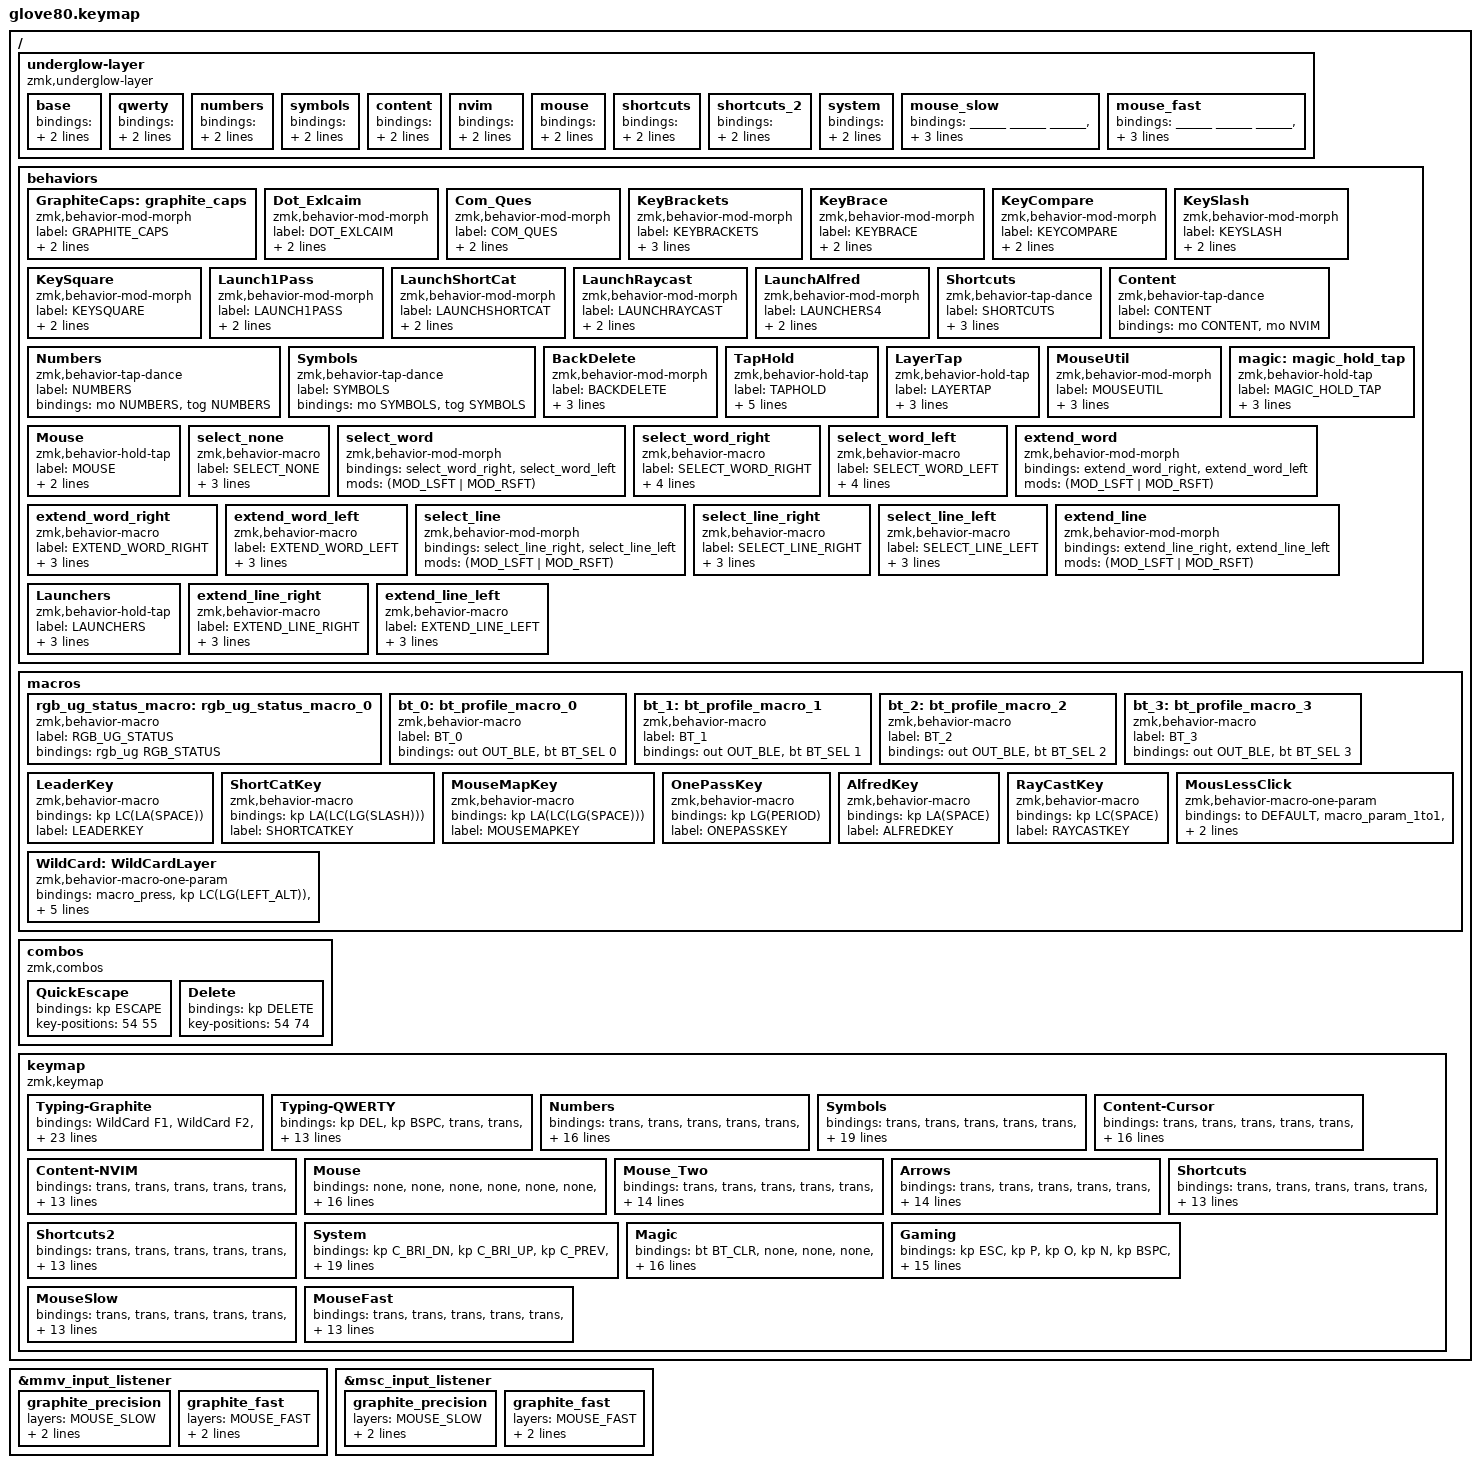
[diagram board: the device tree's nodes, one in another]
/*
 * Graphite update - 2026-10-28
 * Caps Word / Shift+Caps Lock; hold-to-slow/fast mouse; KEYS host shortcut.
 * Graphite letter positions and existing thumb bindings are preserved.
 * Requires the original build's underglow-layer support plus input processors
 * with zip_xy_scaler/zip_scroll_scaler (MoErgo 25.04+ or a compatible fork).
 * See README.md for physical keys, host binding, and validation limitations.
 */
/*
 * Glove 80 Keymap
 *
 * Contents:
 * 1. Includes
 * 2. Layer Defninitons
 * 3. Shortcut Defninitons
 * 4. Color Definitions
 * 5. Layer Colors
 * 6. Color Maps
 * 7. Behaviours
 * 8. macros
 * 9. Combos
 * 10. Keymaps
 *
 */
/************
*  1. Includes
*********************/

#include <behaviors.dtsi>
#include <dt-bindings/zmk/bt.h>
#include <dt-bindings/zmk/keys.h>
#include <dt-bindings/zmk/outputs.h>
#include <dt-bindings/zmk/pointing.h>
#include <input/processors.dtsi>
#include <dt-bindings/zmk/rgb.h>

/************
*  2. Layer Defninitons
*********************/

#define DEFAULT        0
#define QWERTY         1
#define NUMBERS        2
#define SYMBOLS        3
#define CONTENT        4
#define NVIM           5
#define MOUSE          6
#define MOUSE_SCROLL   7
#define ARROWS         8
#define SHORTCUTS      9
#define SHORTCUTS_2    10
#define SYSTEM         11
#define MAGIC          12
#define GAMING         13
#define MOUSE_SLOW     14
#define MOUSE_FAST     15

/* Mouse scaling: multiplier / divisor. Slow wins if both keys are held.
 * Pointer: normal 1x, slow 1/4x, fast 3x.
 * Scroll: normal 1x, slow 1/2x, fast 2x; horizontal scroll is scaled too.
 */
#define POINTER_SLOW_MULT 1
#define POINTER_SLOW_DIV  4
#define POINTER_FAST_MULT 3
#define POINTER_FAST_DIV  1
#define SCROLL_SLOW_MULT  1
#define SCROLL_SLOW_DIV   2
#define SCROLL_FAST_MULT  2
#define SCROLL_FAST_DIV   1

&mmv_input_listener {
    graphite_precision {
        layers = <MOUSE_SLOW>;
        input-processors = <&zip_xy_scaler POINTER_SLOW_MULT POINTER_SLOW_DIV>;
    };
    graphite_fast {
        layers = <MOUSE_FAST>;
        input-processors = <&zip_xy_scaler POINTER_FAST_MULT POINTER_FAST_DIV>;
    };
};

&msc_input_listener {
    graphite_precision {
        layers = <MOUSE_SLOW>;
        input-processors = <&zip_scroll_scaler SCROLL_SLOW_MULT SCROLL_SLOW_DIV>;
    };
    graphite_fast {
        layers = <MOUSE_FAST>;
        input-processors = <&zip_scroll_scaler SCROLL_FAST_MULT SCROLL_FAST_DIV>;
    };
};

/************
* 3. Shortcut Defninitons
*********************/

#define WildModifier  &kp LC(LG(LEFT_ALT))

/***********
* 4. Color Definitions
*********************/

#define COLOR_BLACK        0x000000
#define COLOR_WHITE        0xFFFFFF
#define COLOR_SKY_BLUE     0x66B3FF
#define COLOR_DEEP_BLUE    0x005F99
#define COLOR_LIGHT_BLUE   0x80CFFF
#define COLOR_BRIGHT_GREEN 0x00E673
#define COLOR_ORANGE       0xFF9933
#define COLOR_PURPLE       0x9900FF
#define COLOR_DEEP_PURPLE  0x0900FF
#define COLOR_DARK_RED     0xB30000
#define COLOR_GOLD         0xC49A21
#define COLOR_DEEP_TEAL    0x005F73

/***********
* 5. Layer Colors
*********************/

#define ______  &ug COLOR_BLACK
#define _DFLT_  &ug COLOR_BLACK
#define _QWTY_  &ug COLOR_WHITE
#define _NMBR_  &ug COLOR_SKY_BLUE
#define _SYMB_  &ug COLOR_DEEP_BLUE
#define _CONT_  &ug COLOR_ORANGE
#define _NVIM_  &ug COLOR_PURPLE
#define _MSE__  &ug COLOR_BRIGHT_GREEN
#define _MSEF_  &ug COLOR_BRIGHT_GREEN
#define _MSES_  &ug COLOR_BRIGHT_GREEN
#define _HLP__  &ug COLOR_DEEP_TEAL
#define _HLP2_  &ug COLOR_DEEP_TEAL
#define _SYST_  &ug COLOR_DARK_RED
#define _MAGC_  &ug COLOR_GOLD

/***********
 * 6. Color Maps
*********************/
/* Blank Example:

    mylayer {
        bindings = <
______ ______ ______ ______ ______                                                                    ______ ______ ______ ______ ______
______ ______ ______ ______ ______ ______                                                      ______ ______ ______ ______ ______ ______
______ ______ ______ ______ ______ ______                                                      ______ ______ ______ ______ ______ ______
______ ______ ______ ______ ______ ______                                                      ______ ______ ______ ______ ______ ______
______ ______ ______ ______ ______ ______ ______ ______ ______            ______ ______ ______ ______ ______ ______ ______ ______ ______
______ ______ ______ ______ ______        ______ ______ ______            ______ ______ ______        ______ ______ ______ ______ ______
        >;
        layer-id = <LAYER_Name>;
    };

*/

/ {
    underglow-layer {
        compatible = "zmk,underglow-layer";

        base {
            bindings = <
______ ______ _DFLT_ _DFLT_ _DFLT_                                                                    _DFLT_ _DFLT_ _DFLT_ ______ ______
______ ______ ______ ______ ______ ______                                                      ______ ______ ______ ______ ______ ______
______ ______ ______ ______ ______ ______                                                      ______ ______ ______ ______ ______ ______
______ ______ ______ ______ ______ ______                                                      ______ ______ ______ ______ ______ ______
______ ______ ______ ______ ______ ______ ______ ______ ______            ______ ______ ______ ______ ______ ______ ______ ______ ______
______ ______ ______ ______ ______        ______ ______ ______            ______ ______ ______        ______ ______ ______ ______ ______
            >;

            layer-id = <DEFAULT>;
        };

        qwerty {
            bindings = <
______ ______ _QWTY_ _QWTY_ _QWTY_                                                                    _QWTY_ _QWTY_ _QWTY_ ______ ______
______ ______ ______ ______ ______ ______                                                      ______ ______ ______ ______ ______ ______
______ ______ ______ ______ ______ ______                                                      ______ ______ ______ ______ ______ ______
______ ______ ______ ______ ______ ______                                                      ______ ______ ______ ______ ______ ______
______ ______ ______ ______ ______ ______ ______ ______ ______            ______ ______ ______ ______ ______ ______ ______ ______ ______
______ ______ ______ ______ ______        ______ ______ ______            ______ ______ ______        ______ ______ ______ ______ ______
            >;

            layer-id = <QWERTY>;
        };

        numbers {
            bindings = <
______ ______ _NMBR_ _NMBR_ _NMBR_                                                                    _NMBR_ _NMBR_ _NMBR_ ______ ______
______ ______ ______ ______ ______ ______                                                      ______ ______ ______ ______ ______ ______
______ ______ ______ ______ ______ ______                                                      ______ ______ ______ ______ ______ ______
______ ______ ______ ______ ______ ______                                                      ______ ______ ______ ______ ______ ______
______ ______ ______ ______ ______ ______ ______ ______ ______            ______ ______ ______ ______ ______ ______ ______ ______ ______
______ ______ ______ ______ ______        ______ ______ ______            ______ ______ ______        ______ ______ ______ ______ ______
            >;

            layer-id = <NUMBERS>;
        };

        symbols {
            bindings = <
______ ______ _SYMB_ _SYMB_ _SYMB_                                                                    _SYMB_ _SYMB_ _SYMB_ ______ ______
______ ______ ______ ______ ______ ______                                                      ______ ______ ______ ______ ______ ______
______ ______ ______ ______ ______ ______                                                      ______ ______ ______ ______ ______ ______
______ ______ ______ ______ ______ ______                                                      ______ ______ ______ ______ ______ ______
______ ______ ______ ______ ______ ______ ______ ______ ______            ______ ______ ______ ______ ______ ______ ______ ______ ______
______ ______ ______ ______ ______        ______ ______ ______            ______ ______ ______        ______ ______ ______ ______ ______
            >;

            layer-id = <SYMBOLS>;
        };

        content {
            bindings = <
______ ______ _CONT_ _CONT_ _CONT_                                                                    _CONT_ _CONT_ _CONT_ ______ ______
______ ______ ______ ______ ______ ______                                                      ______ ______ ______ ______ ______ ______
______ ______ ______ ______ ______ ______                                                      ______ ______ ______ ______ ______ ______
______ ______ ______ ______ ______ ______                                                      ______ ______ ______ ______ ______ ______
______ ______ ______ ______ ______ ______ ______ ______ ______            ______ ______ ______ ______ ______ ______ ______ ______ ______
______ ______ ______ ______ ______        ______ ______ ______            ______ ______ ______        ______ ______ ______ ______ ______
            >;

            layer-id = <CONTENT>;
        };

        nvim {
            bindings = <
______ ______ _NVIM_ _NVIM_ _NVIM_                                                                    _NVIM_ _NVIM_ _NVIM_ ______ ______
______ ______ ______ ______ ______ ______                                                      ______ ______ ______ ______ ______ ______
______ ______ ______ ______ ______ ______                                                      ______ ______ ______ ______ ______ ______
______ ______ ______ ______ ______ ______                                                      ______ ______ ______ ______ ______ ______
______ ______ ______ ______ ______ ______ ______ ______ ______            ______ ______ ______ ______ ______ ______ ______ ______ ______
______ ______ ______ ______ ______        ______ ______ ______            ______ ______ ______        ______ ______ ______ ______ ______
            >;

            layer-id = <NVIM>;
        };

        mouse {
            bindings = <
______ ______ ______ _MSE__ ______                                                                    ______ _MSE__ ______ ______ ______
______ ______ ______ ______ ______ ______                                                      ______ ______ ______ ______ ______ ______
______ ______ ______ ______ ______ ______                                                      ______ ______ ______ ______ ______ ______
______ ______ ______ ______ ______ ______                                                      ______ ______ ______ ______ ______ ______
______ ______ ______ ______ ______ ______ ______ ______ ______            ______ ______ ______ ______ ______ ______ ______ ______ ______
______ ______ ______ ______ ______        ______ ______ ______            ______ ______ ______        ______ ______ ______ ______ ______
            >;

            layer-id = <MOUSE>;
        };

        shortcuts {
            bindings = <
______ ______ ______ ______ _HLP__                                                                    _HLP__ ______ ______ ______ ______
______ ______ ______ ______ ______ ______                                                      ______ ______ ______ ______ ______ ______
______ ______ ______ ______ ______ ______                                                      ______ ______ ______ ______ ______ ______
______ ______ ______ ______ ______ ______                                                      ______ ______ ______ ______ ______ ______
______ ______ ______ ______ ______ ______ ______ ______ ______            ______ ______ ______ ______ ______ ______ ______ ______ ______
______ ______ ______ ______ ______        ______ ______ ______            ______ ______ ______        ______ ______ ______ ______ ______
            >;

            layer-id = <SHORTCUTS>;
        };

        shortcuts_2 {
            bindings = <
______ ______ ______ _HLP2_ _HLP2_                                                                    _HLP2_ _HLP2_ ______ ______ ______
______ ______ ______ ______ ______ ______                                                      ______ ______ ______ ______ ______ ______
______ ______ ______ ______ ______ ______                                                      ______ ______ ______ ______ ______ ______
______ ______ ______ ______ ______ ______                                                      ______ ______ ______ ______ ______ ______
______ ______ ______ ______ ______ ______ ______ ______ ______            ______ ______ ______ ______ ______ ______ ______ ______ ______
______ ______ ______ ______ ______        ______ ______ ______            ______ ______ ______        ______ ______ ______ ______ ______
            >;

            layer-id = <SHORTCUTS_2>;
        };

        system {
            bindings = <
______ ______ _SYST_ _SYST_ _SYST_                                                                    _SYST_ _SYST_ _SYST_ ______ ______
______ ______ ______ ______ ______ ______                                                      ______ ______ ______ ______ ______ ______
______ ______ ______ ______ ______ ______                                                      ______ ______ ______ ______ ______ ______
______ ______ ______ ______ ______ ______                                                      ______ ______ ______ ______ ______ ______
______ ______ ______ ______ ______ ______ ______ ______ ______            ______ ______ ______ ______ ______ ______ ______ ______ ______
______ ______ ______ ______ ______        ______ ______ ______            ______ ______ ______        ______ ______ ______ ______ ______
            >;

            layer-id = <SYSTEM>;
        };

        mouse_slow {
            bindings = <
                ______  ______  ______  &ug COLOR_LIGHT_BLUE  ______  ______  &ug COLOR_LIGHT_BLUE  ______  ______  ______
                ______  ______  ______  ______  ______  ______  ______  ______  ______  ______  ______  ______
                ______  ______  ______  ______  ______  ______  ______  ______  ______  ______  ______  ______
                ______  ______  ______  ______  ______  ______  ______  ______  ______  ______  ______  ______
                ______  ______  ______  ______  ______  ______  ______  ______  ______  ______  ______  ______  ______  ______  ______  ______  ______  ______
                ______  ______  ______  ______  ______  ______  ______  ______  ______  ______  ______  ______  ______  ______  ______  ______
            >;
            layer-id = <MOUSE_SLOW>;
        };

        mouse_fast {
            bindings = <
                ______  ______  ______  &ug COLOR_ORANGE  ______  ______  &ug COLOR_ORANGE  ______  ______  ______
                ______  ______  ______  ______  ______  ______  ______  ______  ______  ______  ______  ______
                ______  ______  ______  ______  ______  ______  ______  ______  ______  ______  ______  ______
                ______  ______  ______  ______  ______  ______  ______  ______  ______  ______  ______  ______
                ______  ______  ______  ______  ______  ______  ______  ______  ______  ______  ______  ______  ______  ______  ______  ______  ______  ______
                ______  ______  ______  ______  ______  ______  ______  ______  ______  ______  ______  ______  ______  ______  ______  ______
            >;
            layer-id = <MOUSE_FAST>;
        };
    };
};

/***********
 * 7. Behaviours
*********************/

/ {
    behaviors {

        // Tap: Caps Word. Hold either Shift and tap: ordinary Caps Lock.
        GraphiteCaps: graphite_caps {
            compatible = "zmk,behavior-mod-morph";
            label = "GRAPHITE_CAPS";
            #binding-cells = <0>;
            bindings = <&caps_word>, <&kp CAPSLOCK>;
            mods = <(MOD_LSFT | MOD_RSFT)>;
        };

        /*****
    /* 7a. Keypairs
    /**********/

        Dot_Exlcaim: Dot_Exlcaim {
            compatible = "zmk,behavior-mod-morph";
            label = "DOT_EXLCAIM";
            bindings = <&kp PERIOD>, <&kp EXCLAMATION>;

            #binding-cells = <0>;
            mods = <(MOD_RSFT|MOD_LSFT)>;
        };

        Com_Ques: Com_Ques {
            compatible = "zmk,behavior-mod-morph";
            label = "COM_QUES";
            bindings = <&kp COMMA>, <&kp QUESTION>;

            #binding-cells = <0>;
            mods = <(MOD_RSFT|MOD_LSFT)>;
        };

        KeyBrackets: KeyBrackets {
            compatible = "zmk,behavior-mod-morph";
            label = "KEYBRACKETS";
            bindings = <&kp LEFT_PARENTHESIS>, <&kp RIGHT_PARENTHESIS>;

            #binding-cells = <0>;
            mods = <(MOD_RSFT|MOD_LSFT)>;
        };

        KeyBrace: KeyBrace {
            compatible = "zmk,behavior-mod-morph";
            label = "KEYBRACE";
            bindings = <&kp LEFT_BRACE>, <&kp RIGHT_BRACE>;

            #binding-cells = <0>;
            mods = <(MOD_RSFT|MOD_LSFT)>;
        };

        KeyCompare: KeyCompare {
            compatible = "zmk,behavior-mod-morph";
            label = "KEYCOMPARE";
            bindings = <&kp LESS_THAN>, <&kp GREATER_THAN>;

            #binding-cells = <0>;
            mods = <(MOD_RSFT|MOD_LSFT)>;
        };

        KeySlash: KeySlash {
            compatible = "zmk,behavior-mod-morph";
            label = "KEYSLASH";
            bindings = <&kp SLASH>, <&kp BACKSLASH>;

            #binding-cells = <0>;
            mods = <(MOD_RSFT|MOD_LSFT)>;
        };

        KeySquare: KeySquare {
            compatible = "zmk,behavior-mod-morph";
            label = "KEYSQUARE";
            bindings = <&kp LEFT_BRACKET>, <&kp RIGHT_BRACKET>;

            #binding-cells = <0>;
            mods = <(MOD_RSFT|MOD_LSFT)>;
        };

        /*****
    /* 7b. Quick Launchers
    /*************/

        Launch1Pass: Launch1Pass {
            compatible = "zmk,behavior-mod-morph";
            label = "LAUNCH1PASS";
            bindings = <&LaunchRaycast>, <&OnePassKey>;

            #binding-cells = <0>;
            mods = <(MOD_LCTL|MOD_RCTL)>;
        };

        LaunchShortCat: LaunchShortCat {
            compatible = "zmk,behavior-mod-morph";
            label = "LAUNCHSHORTCAT";
            bindings = <&LaunchRaycast>, <&ShortCatKey>;

            #binding-cells = <0>;
            mods = <(MOD_RALT|MOD_LALT)>;
        };

        LaunchRaycast: LaunchRaycast {
            compatible = "zmk,behavior-mod-morph";
            label = "LAUNCHRAYCAST";
            bindings = <&LaunchAlfred>, <&RayCastKey>;

            #binding-cells = <0>;
            mods = <(MOD_LALT|MOD_RALT)>;
        };

        LaunchAlfred: LaunchAlfred {
            compatible = "zmk,behavior-mod-morph";
            label = "LAUNCHERS4";
            bindings = <&AlfredKey>, <&LeaderKey>;

            #binding-cells = <0>;
            mods = <(MOD_RGUI|MOD_LGUI)>;
        };

        /*****
    /* 7c. Layer Toggle Keys
    /*************/

        Shortcuts: Shortcuts {
            compatible = "zmk,behavior-tap-dance";
            label = "SHORTCUTS";
            #binding-cells = <0>;
            bindings = <&kp LC(LG(LEFT_ALT))>, <&mo SHORTCUTS_2>, <&mo SYSTEM>;

            tapping-term-ms = <400>;
        };

        Content: Content {
            compatible = "zmk,behavior-tap-dance";
            label = "CONTENT";
            #binding-cells = <0>;
            bindings = <&mo CONTENT>, <&mo NVIM>;
        };

        Numbers: Numbers {
            compatible = "zmk,behavior-tap-dance";
            label = "NUMBERS";
            #binding-cells = <0>;
            bindings = <&mo NUMBERS>, <&tog NUMBERS>;
        };

        Symbols: Symbols {
            compatible = "zmk,behavior-tap-dance";
            label = "SYMBOLS";
            #binding-cells = <0>;
            bindings = <&mo SYMBOLS>, <&tog SYMBOLS>;
        };

        /******
    /* 7d. Delete Backspace Functionality 
    /*************/

        BackDelete: BackDelete {
            compatible = "zmk,behavior-mod-morph";
            label = "BACKDELETE";
            bindings = <&kp BACKSPACE>, <&kp DELETE>;

            #binding-cells = <0>;
            mods = <(MOD_RSFT)>;
            keep-mods = <(MOD_RSFT)>;
        };

        /******
    /* 7e. Internal Helpers
    /*************/

        TapHold: TapHold {
            compatible = "zmk,behavior-hold-tap";
            label = "TAPHOLD";
            bindings = <&kp>, <&kp>;

            #binding-cells = <2>;
            tapping-term-ms = <200>;
            flavor = "hold-preferred";
            hold-while-undecided;
            hold-while-undecided-linger;
        };

        LayerTap: LayerTap {
            compatible = "zmk,behavior-hold-tap";
            label = "LAYERTAP";
            bindings = <&mo>, <&tog>;

            #binding-cells = <2>;
            tapping-term-ms = <150>;
            hold-while-undecided;
        };

        MouseUtil: MouseUtil {
            compatible = "zmk,behavior-mod-morph";
            label = "MOUSEUTIL";
            bindings = <&MouseMapKey>, <&ShortCatKey>;

            #binding-cells = <0>;
            mods = <(MOD_LCTL|MOD_LSFT|MOD_LALT|MOD_LGUI|MOD_RCTL|MOD_RALT|MOD_RSFT|MOD_RGUI)>;
        };

        /******
    /* 7f. Magic Layer/Core
    /*************/

        magic: magic_hold_tap {
            compatible = "zmk,behavior-hold-tap";
            label = "MAGIC_HOLD_TAP";
            #binding-cells = <2>;
            flavor = "tap-preferred";
            tapping-term-ms = <200>;
            bindings = <&mo>, <&rgb_ug_status_macro>;
        };

        Mouse: Mouse {
            compatible = "zmk,behavior-hold-tap";
            label = "MOUSE";
            bindings = <&mo>, <&MouseUtil>;

            #binding-cells = <2>;
            tapping-term-ms = <400>;
        };

        /******
    * 7g. Content Control
    *************/
        // SELECT_WORD_DELAY defines how long the macro waits (milliseconds)
        // after moving the cursor before it selects a word. A larger delay
        // may allow the macro to move to the next word upon each invocation.
        //

        #ifndef SELECT_WORD_DELAY
        #define SELECT_WORD_DELAY 1
        #endif

        #define select_all &kp LC(A)

        // Select None Macro

        select_none: select_none {
            compatible = "zmk,behavior-macro";
            #binding-cells = <0>;
            label = "SELECT_NONE";
            bindings = <&kp DOWN &kp UP &kp RIGHT &kp LEFT>;
            wait-ms = <SELECT_WORD_DELAY>;
            tap-ms = <SELECT_WORD_DELAY>;
        };

        // Select a word (jumps to the next word upon each successive invocation)

        select_word: select_word {
            compatible = "zmk,behavior-mod-morph";
            #binding-cells = <0>;
            bindings = <&select_word_right>, <&select_word_left>;

            mods = <(MOD_LSFT | MOD_RSFT)>;
        };

        // Move Right and Select a Word

        select_word_right: select_word_right {
            compatible = "zmk,behavior-macro";
            #binding-cells = <0>;
            label = "SELECT_WORD_RIGHT";
            bindings = <&kp LA(RIGHT) &kp LA(LEFT) &kp LS(LA(RIGHT))>;
            wait-ms = <SELECT_WORD_DELAY>;
            tap-ms = <SELECT_WORD_DELAY>;
        };

        // Move Left and Select a Word

        select_word_left: select_word_left {
            compatible = "zmk,behavior-macro";
            #binding-cells = <0>;
            label = "SELECT_WORD_LEFT";
            bindings = <&kp LA(LEFT) &kp LA(RIGHT) &kp LS(LA(LEFT))>;
            wait-ms = <SELECT_WORD_DELAY>;
            tap-ms = <SELECT_WORD_DELAY>;
        };

        // Extend current selection by one word

        extend_word: extend_word {
            compatible = "zmk,behavior-mod-morph";
            #binding-cells = <0>;
            bindings = <&extend_word_right>, <&extend_word_left>;

            mods = <(MOD_LSFT | MOD_RSFT)>;
        };

        // Extend selection to the right by one word

        extend_word_right: extend_word_right {
            compatible = "zmk,behavior-macro";
            #binding-cells = <0>;
            label = "EXTEND_WORD_RIGHT";
            bindings = <&kp LS(LA(RIGHT))>;
            wait-ms = <SELECT_WORD_DELAY>;
            tap-ms = <SELECT_WORD_DELAY>;
        };

        // Extend selection to the left by one word

        extend_word_left: extend_word_left {
            compatible = "zmk,behavior-macro";
            #binding-cells = <0>;
            label = "EXTEND_WORD_LEFT";
            bindings = <&kp LS(LA(LEFT))>;
            wait-ms = <SELECT_WORD_DELAY>;
            tap-ms = <SELECT_WORD_DELAY>;
        };

        // Select the entire line

        select_line: select_line {
            compatible = "zmk,behavior-mod-morph";
            #binding-cells = <0>;
            bindings = <&select_line_right>, <&select_line_left>;

            mods = <(MOD_LSFT | MOD_RSFT)>;
        };

        // Select the current line (move cursor to start and then select)

        select_line_right: select_line_right {
            compatible = "zmk,behavior-macro";
            #binding-cells = <0>;
            label = "SELECT_LINE_RIGHT";
            bindings = <&kp LG(LEFT) &kp LS(LG(RIGHT))>;
            wait-ms = <SELECT_WORD_DELAY>;
            tap-ms = <SELECT_WORD_DELAY>;
        };

        // Select the current line (move cursor to end and then select backward)

        select_line_left: select_line_left {
            compatible = "zmk,behavior-macro";
            #binding-cells = <0>;
            label = "SELECT_LINE_LEFT";
            bindings = <&kp LG(RIGHT) &kp LS(LG(LEFT))>;
            wait-ms = <SELECT_WORD_DELAY>;
            tap-ms = <SELECT_WORD_DELAY>;
        };

        // Extend selection to the next line

        extend_line: extend_line {
            compatible = "zmk,behavior-mod-morph";
            #binding-cells = <0>;
            bindings = <&extend_line_right>, <&extend_line_left>;

            mods = <(MOD_LSFT | MOD_RSFT)>;
        };

        Launchers: Launchers {
            compatible = "zmk,behavior-hold-tap";
            label = "LAUNCHERS";
            bindings = <&Shortcuts>, <&Launch1Pass>;

            #binding-cells = <2>;
            tapping-term-ms = <300>;
            hold-while-undecided;
        };

        // Extend selection to the next line downward

        extend_line_right: extend_line_right {
            compatible = "zmk,behavior-macro";
            #binding-cells = <0>;
            label = "EXTEND_LINE_RIGHT";
            bindings = <&kp LS(DOWN) &kp LS(LG(RIGHT))>;
            wait-ms = <SELECT_WORD_DELAY>;
            tap-ms = <SELECT_WORD_DELAY>;
        };

        // Extend selection to the previous line upward

        extend_line_left: extend_line_left {
            compatible = "zmk,behavior-macro";
            #binding-cells = <0>;
            label = "EXTEND_LINE_LEFT";
            bindings = <&kp LS(UP) &kp LS(LG(LEFT))>;
            wait-ms = <SELECT_WORD_DELAY>;
            tap-ms = <SELECT_WORD_DELAY>;
        };
    };
};

/***********
* 8. macros
*********************/

/ {
    macros {
        /******
    /* 8a. Glove80 Core
    /*************/

        rgb_ug_status_macro: rgb_ug_status_macro_0 {
            label = "RGB_UG_STATUS";
            compatible = "zmk,behavior-macro";
            #binding-cells = <0>;
            bindings = <&rgb_ug RGB_STATUS>;
        };

        bt_0: bt_profile_macro_0 {
            label = "BT_0";
            compatible = "zmk,behavior-macro";
            #binding-cells = <0>;
            bindings = <&out OUT_BLE &bt BT_SEL 0>;
        };

        bt_1: bt_profile_macro_1 {
            label = "BT_1";
            compatible = "zmk,behavior-macro";
            #binding-cells = <0>;
            bindings = <&out OUT_BLE &bt BT_SEL 1>;
        };

        bt_2: bt_profile_macro_2 {
            label = "BT_2";
            compatible = "zmk,behavior-macro";
            #binding-cells = <0>;
            bindings = <&out OUT_BLE &bt BT_SEL 2>;
        };

        bt_3: bt_profile_macro_3 {
            label = "BT_3";
            compatible = "zmk,behavior-macro";
            #binding-cells = <0>;
            bindings = <&out OUT_BLE &bt BT_SEL 3>;
        };

        /******
    /* 8b. Shortcut Keys
    /*************/

        LeaderKey: LeaderKey {
            compatible = "zmk,behavior-macro";
            #binding-cells = <0>;
            bindings = <&kp LC(LA(SPACE))>;
            label = "LEADERKEY";
        };

        ShortCatKey: ShortCatKey {
            compatible = "zmk,behavior-macro";
            #binding-cells = <0>;
            bindings = <&kp LA(LC(LG(SLASH)))>;
            label = "SHORTCATKEY";
        };

        MouseMapKey: MouseMapKey {
            compatible = "zmk,behavior-macro";
            #binding-cells = <0>;
            bindings = <&kp LA(LC(LG(SPACE)))>;
            label = "MOUSEMAPKEY";
        };

        OnePassKey: OnePassKey {
            compatible = "zmk,behavior-macro";
            #binding-cells = <0>;
            bindings = <&kp LG(PERIOD)>;
            label = "ONEPASSKEY";
        };

        AlfredKey: AlfredKey {
            compatible = "zmk,behavior-macro";
            #binding-cells = <0>;
            bindings = <&kp LA(SPACE)>;
            label = "ALFREDKEY";
        };

        RayCastKey: RayCastKey {
            compatible = "zmk,behavior-macro";
            #binding-cells = <0>;
            bindings = <&kp LC(SPACE)>;
            label = "RAYCASTKEY";
        };

        MousLessClick: MousLessClick {
            compatible = "zmk,behavior-macro-one-param";
            #binding-cells = <1>;
            bindings = <&to DEFAULT &macro_param_1to1 &kp MACRO_PLACEHOLDER>;
            label = "MOUSLESSCLICK";
        };

        /*********
    /* 8c. Wilds
    /*************/

        WildCard: WildCardLayer {
            compatible = "zmk,behavior-macro-one-param";
            #binding-cells = <1>;
            bindings =
                <&macro_press>,
                <&kp LC(LG(LEFT_ALT))>,
                <&macro_tap>,
                <&macro_param_1to1 &kp MACRO_PLACEHOLDER>,
                <&macro_release>,
                <&kp LC(LG(LEFT_ALT))>;

            tap-ms = <300>;
            label = "WILDCARDLAYER";
        };
    };
};

/***********
* 9. Combos
*********************/

/ {
    combos {
        compatible = "zmk,combos";

        QuickEscape {
            bindings = <&kp ESCAPE>;
            key-positions = <54 55>;
        };

        Delete {
            bindings = <&kp DELETE>;
            key-positions = <54 74>;
        };
    };
};

/***********
* 10. Keymaps
*********************/

/ {
    keymap {
        compatible = "zmk,keymap";

        Typing-Graphite {
            bindings = <
&WildCard F1    &WildCard F2  &WildCard F14     &WildCard F15  &WildCard F16                                                                                                                                                    &WildCard F17      &WildCard F18  &WildCard F19      &WildCard F9                               &WildCard F10
&kp GRAVE       &KeySlash     &KeySquare        &KeyBrace      &KeyBrackets      &KeyCompare                                                                                                                     &kp GRAVE      &kp MINUS          &kp EQUAL      &KeySlash          &kp PIPE                                   &kp LC(LA(LG(LS(F13))))
&GraphiteCaps    &kp B         &kp L             &kp D          &kp W             &kp Z                                                                                                                           &kp K          &kp F              &kp O          &kp U              &kp J                                      &kp ESCAPE
&Mouse MOUSE 0      &kp N         &kp R             &kp T          &kp S             &kp G                                                                                                                           &kp Y          &kp H              &kp A          &kp E              &kp I                                      &kp TAB
&kp LEFT_SHIFT  &kp Q         &kp X             &kp M          &kp C             &kp V        &kp SPACE  &Numbers          &TapHold LC(LG(LEFT_ALT)) LA(LC(LG(F20)))  &Content        &Symbols   &kp LEFT_SHIFT  &kp SEMICOLON  &kp P              &Com_Ques      &Dot_Exlcaim       &kp SQT                                    &kp DEL
&magic MAGIC 0     &Mouse MOUSE 0    &kp LEFT_CONTROL  &kp LEFT_ALT   &kp LEFT_COMMAND               &mo ARROWS      &kp LEFT_COMMAND  &kp LC(LEFT_ALT)                           &Launchers 0 0  &kp ENTER  &kp BACKSPACE                  &kp RIGHT_COMMAND  &kp RIGHT_ALT  &kp RIGHT_CONTROL  &TapHold LC(LG(LEFT_ALT)) LA(LC(LG(F24)))  &kp ESCAPE
            >;
        };

        Typing-QWERTY {
            bindings = <
&kp DEL  &kp BSPC  &trans  &trans  &trans                                                                  &trans  &trans     &trans   &trans    &trans
&trans   &kp N1    &kp N2  &kp N3  &kp N4  &kp N5                                                  &kp N6  &kp N7  &kp N8     &kp N9   &kp N0    &kp MINUS
&kp TAB  &kp Q     &kp W   &kp E   &kp R   &kp T                                                   &kp Y   &kp U   &kp I      &kp O    &kp P     &kp LBKT
&trans   &kp A     &kp S   &kp D   &kp F   &kp G                                                   &kp H   &kp J   &kp K      &kp L    &kp SEMI  &trans
&trans   &kp Z     &kp X   &kp C   &kp V   &kp B   &trans  &trans  &trans  &trans  &trans  &trans  &kp N   &kp M   &kp COMMA  &kp DOT  &kp FSLH  &trans
&trans   &trans    &trans  &trans  &trans          &trans  &trans  &trans  &trans  &trans  &trans          &trans  &trans     &trans   &trans    &trans
            >;
        };

        Numbers {
            bindings = <
&trans  &trans                &trans                 &trans       &trans                                                                               &trans    &trans    &trans     &trans     &trans
&trans  &trans                &trans                 &trans       &trans     &trans                                                       &kp PERCENT  &kp FSLH  &kp STAR  &trans     &trans     &trans
&trans  &kp LEFT_PARENTHESIS  &kp RIGHT_PARENTHESIS  &kp PERIOD   &kp EQUAL  &kp COMMA                                                    &kp DOLLAR   &kp N7    &kp N8    &kp N9     &kp MINUS  &trans
&trans  &kp SLASH             &kp ASTERISK           &kp MINUS    &kp PLUS   &kp COLON                                                    &kp HASH     &kp N4    &kp N5    &kp N6     &kp PLUS   &trans
&trans  &trans                &kp DOLLAR             &kp PERCENT  &kp HASH   &trans     &trans  &trans  &trans  &trans  &trans  &Symbols  &kp COMMA    &kp N1    &kp N2    &kp N3     &kp EQUAL  &trans
&trans  &trans                &trans                 &trans       &trans                &trans  &trans  &trans  &trans  &trans  &trans                 &kp N0    &kp DOT   &kp EQUAL  &trans     &trans
            >;
        };

        Symbols {
            bindings = <
&trans           &trans         &trans                &trans                 &trans                                                                                                &trans           &trans        &trans                &trans  &trans
&kp GRAVE        &kp LBKT       &kp EQUAL             &kp UNDERSCORE         &kp RBKT          &kp DOT                                                                     &trans  &trans           &trans        &trans                &trans  &trans
&kp EXCLAMATION  &kp COMMA      &kp LEFT_BRACE        &kp RIGHT_BRACE        &kp SEMI          &kp QUESTION                                                                &trans  &kp AMPS         &kp ASTERISK  &kp LEFT_PARENTHESIS  &trans  &trans
&kp POUND        &kp CARET      &kp LEFT_PARENTHESIS  &kp RIGHT_PARENTHESIS  &kp DOLLAR        &kp ASTERISK                                                                &trans  &kp DLLR         &kp PRCNT     &kp CARET             &trans  &trans
&kp TILDE        &kp PIPE       &kp LESS_THAN         &kp GREATER_THAN       &kp GREATER_THAN  &kp FSLH      &kp BSLH     &kp DOT    &kp ASTERISK  &trans  &trans  &trans  &trans  &kp EXCLAMATION  &kp AT        &kp HASH              &trans  &trans
&trans           &kp AMPERSAND  &kp SQT               &kp DOUBLE_QUOTES      &kp PLUS                        &kp PERCENT  &kp COLON  &kp AT_SIGN   &trans  &trans  &trans          &trans           &trans        &trans                &trans  &trans
            >;
        };

        Content-Cursor {
            bindings = <
&trans  &trans        &trans     &trans        &trans                                                                                  &trans         &trans         &trans         &trans  &trans
&trans  &trans        &trans     &trans        &trans        &trans                                                         &trans     &kp LG(N0)     &kp LG(MINUS)  &kp LG(EQUAL)  &trans  &trans
&trans  &trans        &trans     &extend_line  &extend_word  &trans                                                         &kp LG(Z)  &kp PAGE_UP    &kp LG(EQUAL)  &kp HOME       &trans  &trans
&trans  &select_none  &kp LG(A)  &select_line  &select_word  &trans                                                         &kp LG(Y)  &kp PAGE_DOWN  &kp LG(N0)     &kp END        &trans  &trans
&trans  &trans        &kp LG(X)  &kp LG(C)     &kp LG(V)     &kp LG(LS(V))  &trans  &trans  &trans  &trans  &trans  &trans  &trans     &trans         &kp LG(MINUS)  &trans         &trans  &trans
&trans  &trans        &trans     &trans        &trans                       &trans  &mo NVIM   &trans  &trans  &trans  &trans             &trans         &trans         &trans         &trans  &trans
            >;
        };

        Content-NVIM {
            bindings = <
&trans  &trans  &trans  &trans  &trans                                                                  &trans  &trans  &trans  &trans  &trans
&trans  &trans  &trans  &trans  &trans  &trans                                                  &trans  &trans  &trans  &trans  &trans  &trans
&trans  &trans  &trans  &trans  &trans  &trans                                                  &trans  &trans  &trans  &trans  &trans  &trans
&trans  &trans  &trans  &trans  &trans  &trans                                                  &trans  &trans  &trans  &trans  &trans  &trans
&trans  &trans  &kp X   &kp Y   &kp P   &trans  &trans  &trans  &trans  &trans  &trans  &trans  &trans  &trans  &trans  &trans  &trans  &trans
&trans  &trans  &trans  &trans  &trans          &trans  &trans  &trans  &trans  &trans  &trans          &trans  &trans  &trans  &trans  &trans
            >;
        };

        Mouse {
            bindings = <
&none  &none      &none         &none         &none                                                                                                     &none              &none              &none             &none  &none
&none  &none      &none         &none         &none         &none                                                                       &none           &none              &none              &none             &none  &none
&none  &mo MOUSE_SLOW      &mo MOUSE_FAST         &kp UP        &none         &kp PAGE_UP                                                                 &msc SCRL_UP    &mkp LCLK          &mmv MOVE_Y(-600)  &mkp RCLK         &none  &none
&none  &kp EQUAL  &kp LEFT      &kp DOWN      &kp RIGHT     &kp PAGE_DOWN                                                               &msc SCRL_DOWN  &mmv MOVE_X(-600)  &mmv MOVE_Y(600)   &mmv MOVE_X(600)  &none  &none
&none  &none      &select_none  &select_line  &select_word  &none          &mkp MB4  &mkp MB5  &trans  &none      &mo ARROWS      &mo MOUSE_SCROLL      &none           &mkp LCLK          &mkp MCLK          &mkp RCLK         &none  &none
&none  &none      &trans        &extend_line  &trans                       &trans    &none     &none   &mkp MCLK  &mkp RCLK  &mkp LCLK                  &none              &none              &none             &none  &none
            >;
        };

        Mouse_Two {
            bindings = <
&trans  &trans  &trans  &trans  &trans                                                                  &trans          &trans          &trans           &trans  &trans
&trans  &trans  &trans  &trans  &trans  &trans                                                  &trans  &trans          &trans          &trans           &trans  &trans
&trans  &trans  &trans  &trans  &trans  &trans                                                  &trans  &trans          &msc SCRL_UP    &trans           &trans  &trans
&trans  &trans  &trans  &trans  &trans  &trans                                                  &trans  &msc SCRL_LEFT  &msc SCRL_DOWN  &msc SCRL_RIGHT  &trans  &trans
&trans  &trans  &trans  &trans  &trans  &trans  &trans  &mo MOUSE_SCROLL   &trans  &trans  &trans  &trans  &trans  &trans          &trans          &trans           &trans  &trans
&trans  &trans  &trans  &trans  &trans          &trans  &trans  &trans  &trans  &trans  &trans          &trans          &trans          &trans           &trans  &trans
            >;
        };

        Arrows {
            bindings = <
&trans  &trans  &trans  &trans  &trans                                                                           &trans          &trans          &trans           &trans  &trans
&trans  &trans  &trans  &trans  &trans  &trans                                                           &trans  &trans          &trans          &trans           &trans  &trans
&trans  &trans  &trans  &trans  &trans  &trans                                                           &trans  &trans          &kp UP_ARROW    &trans           &trans  &trans
&trans  &trans  &trans  &trans  &trans  &trans                                                           &trans  &kp LEFT_ARROW  &kp DOWN_ARROW  &kp RIGHT_ARROW  &trans  &trans
&trans  &trans  &trans  &trans  &trans  &trans  &trans  &trans  &trans  &trans     &trans     &trans     &trans  &trans          &trans          &trans           &trans  &trans
&trans  &trans  &trans  &trans  &mo MOUSE           &trans  &trans  &trans  &mkp MCLK  &mkp RCLK  &mkp LCLK          &trans          &trans          &trans           &trans  &trans
            >;
        };

        Shortcuts {
            bindings = <
&trans  &trans  &trans     &trans       &trans                                                                            &trans  &trans  &trans  &trans  &trans
&trans  &trans  &trans     &trans       &trans      &trans                                                        &trans  &trans  &trans  &trans  &trans  &trans
&trans  &trans  &trans     &trans       &trans      &trans                                                        &trans  &trans  &trans  &trans  &trans  &trans
&trans  &trans  &trans     &trans       &trans      &trans                                                        &trans  &trans  &trans  &trans  &trans  &trans
&trans  &trans  &kp K_CUT  &kp K_PASTE  &kp K_COPY  &trans  &trans  &trans  &trans  &trans  &mkp MB5  &mkp MB4    &trans  &trans  &trans  &trans  &trans  &trans
&trans  &trans  &trans     &trans       &trans              &trans  &trans  &trans  &trans  &trans    &kp ESCAPE          &trans  &trans  &trans  &trans  &trans
            >;
        };

        Shortcuts2 {
            bindings = <
&trans  &trans  &trans  &trans  &trans                                                                  &trans  &trans  &trans  &trans  &trans
&trans  &trans  &trans  &trans  &trans  &trans                                                  &trans  &trans  &trans  &trans  &trans  &trans
&trans  &trans  &trans  &trans  &trans  &trans                                                  &trans  &trans  &trans  &trans  &trans  &trans
&trans  &trans  &trans  &trans  &trans  &trans                                                  &trans  &trans  &trans  &trans  &trans  &trans
&trans  &trans  &trans  &trans  &trans  &trans  &trans  &trans  &trans  &trans  &trans  &trans  &trans  &trans  &trans  &trans  &trans  &trans
&trans  &trans  &trans  &trans  &trans          &trans  &trans  &trans  &trans  &trans  &trans          &trans  &trans  &trans  &trans  &trans
            >;
        };

        System {
            bindings = <
&kp C_BRI_DN  &kp C_BRI_UP  &kp C_PREV      &kp C_NEXT      &kp C_PP                                                                                           &kp C_MUTE  &kp C_VOL_DN  &kp C_VOL_UP  &none            &kp PAUSE_BREAK
&trans        &none         &none           &none           &none            &kp HOME                                                   &kp LEFT_PARENTHESIS   &kp KP_NUM  &kp KP_EQUAL  &kp KP_SLASH  &kp KP_MULTIPLY  &kp PRINTSCREEN
&trans        &none         &none           &kp UP_ARROW    &none            &kp END                                                    &kp RIGHT_PARENTHESIS  &kp KP_N7   &kp KP_N8     &kp KP_N9     &kp KP_MINUS     &kp SCROLLLOCK
&trans        &none         &kp LEFT_ARROW  &kp DOWN_ARROW  &kp RIGHT_ARROW  &kp PG_UP                                                  &kp PERCENT            &kp KP_N4   &kp KP_N5     &kp KP_N6     &kp KP_PLUS      &none
&trans        &kp K_APP     &none           &kp F11         &kp F12          &kp PG_DN  &trans  &trans  &to DEFAULT   &trans  &trans  &trans  &kp COMMA              &kp KP_N1   &kp KP_N2     &kp KP_N3     &kp KP_ENTER     &trans
&magic DEFAULT 0    &kp CAPS      &kp INS         &kp F11         &kp F12                     &trans  &trans  &trans  &trans  &trans  &trans                         &kp KP_N0   &kp KP_N0     &kp KP_DOT    &kp KP_ENTER     &trans
            >;
        };

        Magic {
            bindings = <
&bt BT_CLR   &none            &none            &none            &studio_unlock                                                                            &none        &none  &none  &none  &bt BT_CLR_ALL
&none        &none            &none            &none            &none            &none                                                             &none  &none        &none  &none  &none  &none
&trans       &rgb_ug RGB_SPI  &rgb_ug RGB_SAI  &rgb_ug RGB_HUI  &rgb_ug RGB_BRI  &rgb_ug RGB_TOG                                                   &none  &none        &none  &none  &none  &none
&bootloader  &rgb_ug RGB_SPD  &rgb_ug RGB_SAD  &rgb_ug RGB_HUD  &rgb_ug RGB_BRD  &rgb_ug RGB_EFF                                                   &none  &tog GAMING      &none  &none  &none  &bootloader
&sys_reset   &none            &none            &none            &none            &none            &bt_2  &bt_3  &none         &none  &none  &none  &none  &none        &none  &none  &none  &sys_reset
&none        &none            &none            &none            &bootloader                       &bt_0  &bt_1  &out OUT_USB  &none  &none  &none         &bootloader  &none  &none  &none  &none
            >;
        };

        Gaming {
            bindings = <
&kp ESC  &kp P      &kp O   &kp N   &kp BSPC                                                                                              &kp F1     &kp F2     &kp F3    &kp F4     &kp F5
&kp M    &kp N6     &kp N7  &kp N8  &kp N9    &kp N0                                                                              &kp F6  &kp F7     &kp F8     &kp F9    &kp F10    &kp F11
&kp I    &kp N1     &kp N2  &kp N3  &kp N4    &kp N5                                                                              &kp Y   &kp U      &kp I      &kp O     &kp P      &kp F12
&kp T    &kp TAB    &kp Q   &kp W   &kp E     &kp R                                                                               &kp H   &kp J      &kp K      &kp L     &kp SEMI   &kp APOS
&kp G    &kp LSHFT  &kp A   &kp S   &kp D     &kp F   &kp LSHFT  &kp LALT   &kp ENTER  &kp ESC         &kp UP_ARROW    &kp ENTER  &kp N   &kp M      &kp COMMA  &kp DOT   &kp FSLH   &kp BSLH
&kp B    &kp LCTRL  &kp Z   &kp X   &kp C             &kp SPACE  &kp LCTRL  &kp V      &kp LEFT_ARROW  &kp DOWN_ARROW  &kp RIGHT          &kp MINUS  &kp LBKT   &kp RBKT  &kp EQUAL  &kp GRAVE
            >;
        };

        // Speed-only overlay; existing mouse/scroll/arrows/buttons pass through.
        MouseSlow {
            bindings = <
                &trans  &trans  &trans  &trans  &trans  &trans  &trans  &trans  &trans  &trans
                &trans  &trans  &trans  &trans  &trans  &trans  &trans  &trans  &trans  &trans  &trans  &trans
                &trans  &trans  &trans  &trans  &trans  &trans  &trans  &trans  &trans  &trans  &trans  &trans
                &trans  &trans  &trans  &trans  &trans  &trans  &trans  &trans  &trans  &trans  &trans  &trans
                &trans  &trans  &trans  &trans  &trans  &trans  &trans  &trans  &trans  &trans  &trans  &trans  &trans  &trans  &trans  &trans  &trans  &trans
                &trans  &trans  &trans  &trans  &trans  &trans  &trans  &trans  &trans  &trans  &trans  &trans  &trans  &trans  &trans  &trans
            >;
        };

        // Speed-only overlay; existing mouse/scroll/arrows/buttons pass through.
        MouseFast {
            bindings = <
                &trans  &trans  &trans  &trans  &trans  &trans  &trans  &trans  &trans  &trans
                &trans  &trans  &trans  &trans  &trans  &trans  &trans  &trans  &trans  &trans  &trans  &trans
                &trans  &trans  &trans  &trans  &trans  &trans  &trans  &trans  &trans  &trans  &trans  &trans
                &trans  &trans  &trans  &trans  &trans  &trans  &trans  &trans  &trans  &trans  &trans  &trans
                &trans  &trans  &trans  &trans  &trans  &trans  &trans  &trans  &trans  &trans  &trans  &trans  &trans  &trans  &trans  &trans  &trans  &trans
                &trans  &trans  &trans  &trans  &trans  &trans  &trans  &trans  &trans  &trans  &trans  &trans  &trans  &trans  &trans  &trans
            >;
        };
    };
};
